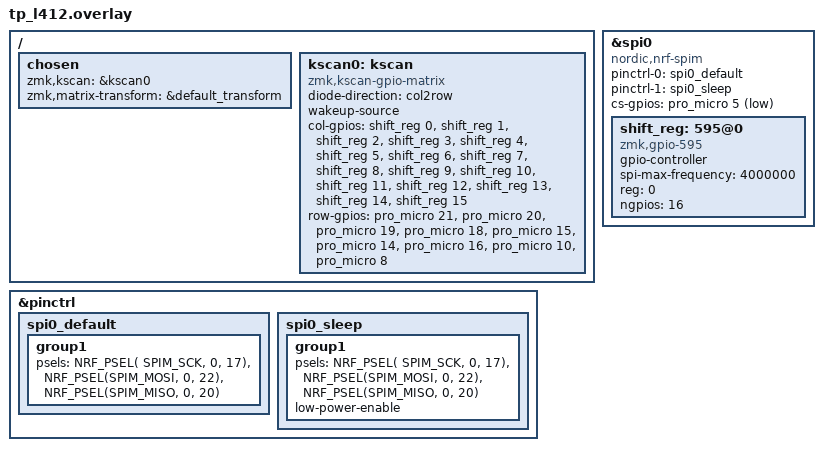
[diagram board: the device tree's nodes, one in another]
#include "tp_l412-matrix.dtsi"
#include "tp_l412-trackpoint.dtsi"
// #include "tp_l412-layouts.dtsi"

/ {
    chosen {
        zmk,kscan = &kscan0;
        zmk,matrix-transform = &default_transform;
        // zmk,physical-layout = &tp_l412_layout;
    };
    
    kscan0: kscan {
        compatible = "zmk,kscan-gpio-matrix";
        diode-direction = "col2row";
        wakeup-source;

        col-gpios
            = <&shift_reg 0 GPIO_ACTIVE_HIGH>
            , <&shift_reg 1 GPIO_ACTIVE_HIGH>
            , <&shift_reg 2 GPIO_ACTIVE_HIGH>
            , <&shift_reg 3 GPIO_ACTIVE_HIGH>
            , <&shift_reg 4 GPIO_ACTIVE_HIGH>
            , <&shift_reg 5 GPIO_ACTIVE_HIGH>
            , <&shift_reg 6 GPIO_ACTIVE_HIGH>
            , <&shift_reg 7 GPIO_ACTIVE_HIGH>
            , <&shift_reg 8 GPIO_ACTIVE_HIGH>
            , <&shift_reg 9 GPIO_ACTIVE_HIGH>
            , <&shift_reg 10 GPIO_ACTIVE_HIGH>
            , <&shift_reg 11 GPIO_ACTIVE_HIGH>
            , <&shift_reg 12 GPIO_ACTIVE_HIGH>
            , <&shift_reg 13 GPIO_ACTIVE_HIGH>
            , <&shift_reg 14 GPIO_ACTIVE_HIGH>
            , <&shift_reg 15 GPIO_ACTIVE_HIGH>
            ;

        row-gpios
            = <&pro_micro 21 (GPIO_ACTIVE_HIGH | GPIO_PULL_DOWN)>
            , <&pro_micro 20 (GPIO_ACTIVE_HIGH | GPIO_PULL_DOWN)>
            , <&pro_micro 19 (GPIO_ACTIVE_HIGH | GPIO_PULL_DOWN)>
            , <&pro_micro 18 (GPIO_ACTIVE_HIGH | GPIO_PULL_DOWN)>
            , <&pro_micro 15 (GPIO_ACTIVE_HIGH | GPIO_PULL_DOWN)>
            , <&pro_micro 14 (GPIO_ACTIVE_HIGH | GPIO_PULL_DOWN)>
            , <&pro_micro 16 (GPIO_ACTIVE_HIGH | GPIO_PULL_DOWN)>
            , <&pro_micro 10 (GPIO_ACTIVE_HIGH | GPIO_PULL_DOWN)>
            , <&pro_micro 8 (GPIO_ACTIVE_HIGH | GPIO_PULL_DOWN)>
            ;
    };
};

&pinctrl {
    spi0_default: spi0_default {
        group1 {
            psels 
                = <NRF_PSEL( SPIM_SCK, 0, 17)> 
                , <NRF_PSEL(SPIM_MOSI, 0, 22)>
                , <NRF_PSEL(SPIM_MISO, 0, 20)>
                ;
        };
    };
    spi0_sleep: spi0_sleep {
        group1 {
            psels 
                = <NRF_PSEL( SPIM_SCK, 0, 17)> 
                , <NRF_PSEL(SPIM_MOSI, 0, 22)>
                , <NRF_PSEL(SPIM_MISO, 0, 20)>
                ;
            low-power-enable;
        };
    };
};

board_spi: &spi0 {
  status = "okay";
  compatible = "nordic,nrf-spim";
  pinctrl-0 = <&spi0_default>;
  pinctrl-1 = <&spi0_sleep>;
  pinctrl-names = "default", "sleep";
  cs-gpios = <&pro_micro 5 GPIO_ACTIVE_LOW> ;

  shift_reg: 595@0 {
    compatible = "zmk,gpio-595";
    status = "okay";
    gpio-controller;
    spi-max-frequency = <4000000>;
    #gpio-cells = <2>;
    reg = <0>;
    ngpios = <16>;
  };
};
